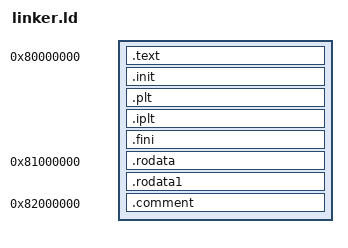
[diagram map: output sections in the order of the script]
/* ---- Original Script: /opt/riscv32i/riscv32-unknown-elf/lib/ldscripts/elf32lriscv.x ---- */
/* Default linker script, for normal executables */
/* Copyright (C) 2014-2017 Free Software Foundation, Inc.
   Copying and distribution of this script, with or without modification,
   are permitted in any medium without royalty provided the copyright
   notice and this notice are preserved.  */
OUTPUT_FORMAT("elf32-littleriscv", "elf32-littleriscv",
	      "elf32-littleriscv")
OUTPUT_ARCH(riscv)
ENTRY(_start)
SECTIONS
{
  . = 0x80000000;
  .text           :
  {
    *(.text)
    *(.text.unlikely .text.*_unlikely .text.unlikely.*)
    *(.text.exit .text.exit.*)
    *(.text.startup .text.startup.*)
    *(.text.hot .text.hot.*)
    *(.stub .text.* .gnu.linkonce.t.*)
    /* .gnu.warning sections are handled specially by elf32.em.  */
    *(.gnu.warning)
  }
  .init           :
  {
    KEEP (*(SORT_NONE(.init)))
  }
  .plt            : { *(.plt) }
  .iplt           : { *(.iplt) }
  .fini           :
  {
    KEEP (*(SORT_NONE(.fini)))
  }
  PROVIDE (__etext = .);
  PROVIDE (_etext = .);
  PROVIDE (etext = .);
  PROVIDE (_edata = .);
  PROVIDE (_end = .);
  PROVIDE (__global_pointer$ = .);

  . = 0x81000000;
  .rodata         : { *(.rodata .rodata.* .gnu.linkonce.r.*) }
  .rodata1        : { *(.rodata1) }
  . = 0x82000000;
  .comment        : { *(.comment) }

}
